AUTOSAR XML (schema 00044)
package /ComponentTypes
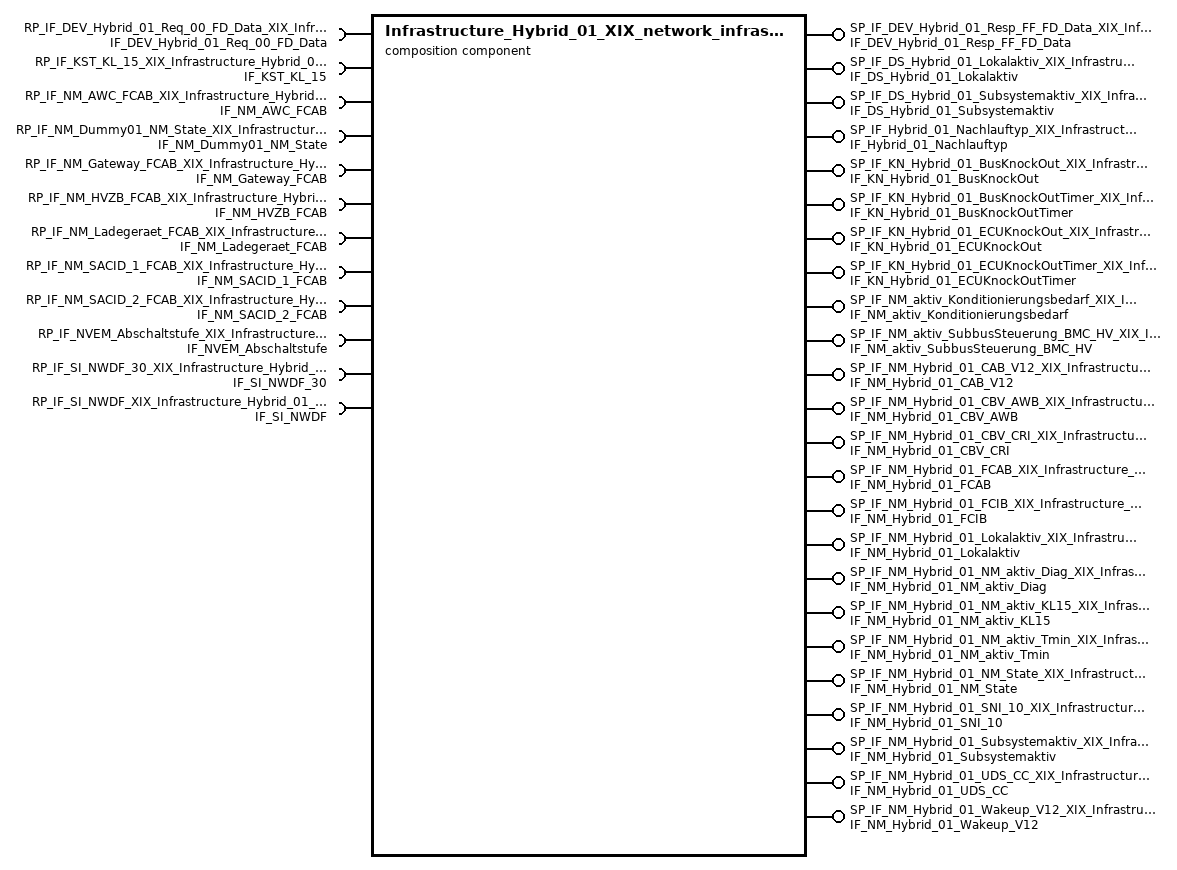
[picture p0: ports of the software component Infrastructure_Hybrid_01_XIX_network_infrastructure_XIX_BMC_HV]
  composition sw component type Infrastructure_Hybrid_01_XIX_network_infrastructure_XIX_BMC_HV
    24 x provide port:
      SP_IF_DEV_Hybrid_01_Resp_FF_FD_Data_XIX_Infrastructure_Hybrid_01_XIX_network_infrastructure_XIX_BMC_HV: nonqueued-sender-com-spec=DE_DEV_Hybrid_01_Resp_FF_FD_Data, provided-interface=IF_DEV_Hybrid_01_Resp_FF_FD_Data
      SP_IF_DS_Hybrid_01_Lokalaktiv_XIX_Infrastructure_Hybrid_01_XIX_network_infrastructure_XIX_BMC_HV: nonqueued-sender-com-spec=DE_DS_Hybrid_01_Lokalaktiv, provided-interface=IF_DS_Hybrid_01_Lokalaktiv
      SP_IF_DS_Hybrid_01_Subsystemaktiv_XIX_Infrastructure_Hybrid_01_XIX_network_infrastructure_XIX_BMC_HV: nonqueued-sender-com-spec=DE_DS_Hybrid_01_Subsystemaktiv, provided-interface=IF_DS_Hybrid_01_Subsystemaktiv
      SP_IF_Hybrid_01_Nachlauftyp_XIX_Infrastructure_Hybrid_01_XIX_network_infrastructure_XIX_BMC_HV: nonqueued-sender-com-spec=DE_Hybrid_01_Nachlauftyp, provided-interface=IF_Hybrid_01_Nachlauftyp
      SP_IF_KN_Hybrid_01_BusKnockOut_XIX_Infrastructure_Hybrid_01_XIX_network_infrastructure_XIX_BMC_HV: nonqueued-sender-com-spec=DE_KN_Hybrid_01_BusKnockOut, provided-interface=IF_KN_Hybrid_01_BusKnockOut
      SP_IF_KN_Hybrid_01_BusKnockOutTimer_XIX_Infrastructure_Hybrid_01_XIX_network_infrastructure_XIX_BMC_HV: nonqueued-sender-com-spec=DE_KN_Hybrid_01_BusKnockOutTimer, provided-interface=IF_KN_Hybrid_01_BusKnockOutTimer
      SP_IF_KN_Hybrid_01_ECUKnockOut_XIX_Infrastructure_Hybrid_01_XIX_network_infrastructure_XIX_BMC_HV: nonqueued-sender-com-spec=DE_KN_Hybrid_01_ECUKnockOut, provided-interface=IF_KN_Hybrid_01_ECUKnockOut
      SP_IF_KN_Hybrid_01_ECUKnockOutTimer_XIX_Infrastructure_Hybrid_01_XIX_network_infrastructure_XIX_BMC_HV: nonqueued-sender-com-spec=DE_KN_Hybrid_01_ECUKnockOutTimer, provided-interface=IF_KN_Hybrid_01_ECUKnockOutTimer
      SP_IF_NM_aktiv_Konditionierungsbedarf_XIX_Infrastructure_Hybrid_01_XIX_network_infrastructure_XIX_BMC_HV: nonqueued-sender-com-spec=DE_NM_aktiv_Konditionierungsbedarf, provided-interface=IF_NM_aktiv_Konditionierungsbedarf
      SP_IF_NM_aktiv_SubbusSteuerung_BMC_HV_XIX_Infrastructure_Hybrid_01_XIX_network_infrastructure_XIX_BMC_HV: nonqueued-sender-com-spec=DE_NM_aktiv_SubbusSteuerung_BMC_HV, provided-interface=IF_NM_aktiv_SubbusSteuerung_BMC_HV
      SP_IF_NM_Hybrid_01_CAB_V12_XIX_Infrastructure_Hybrid_01_XIX_network_infrastructure_XIX_BMC_HV: nonqueued-sender-com-spec=DE_NM_Hybrid_01_CAB_V12, provided-interface=IF_NM_Hybrid_01_CAB_V12
      SP_IF_NM_Hybrid_01_CBV_AWB_XIX_Infrastructure_Hybrid_01_XIX_network_infrastructure_XIX_BMC_HV: nonqueued-sender-com-spec=DE_NM_Hybrid_01_CBV_AWB, provided-interface=IF_NM_Hybrid_01_CBV_AWB
      SP_IF_NM_Hybrid_01_CBV_CRI_XIX_Infrastructure_Hybrid_01_XIX_network_infrastructure_XIX_BMC_HV: nonqueued-sender-com-spec=DE_NM_Hybrid_01_CBV_CRI, provided-interface=IF_NM_Hybrid_01_CBV_CRI
      SP_IF_NM_Hybrid_01_FCAB_XIX_Infrastructure_Hybrid_01_XIX_network_infrastructure_XIX_BMC_HV: nonqueued-sender-com-spec=DE_NM_Hybrid_01_FCAB, provided-interface=IF_NM_Hybrid_01_FCAB
      SP_IF_NM_Hybrid_01_FCIB_XIX_Infrastructure_Hybrid_01_XIX_network_infrastructure_XIX_BMC_HV: nonqueued-sender-com-spec=DE_NM_Hybrid_01_FCIB, provided-interface=IF_NM_Hybrid_01_FCIB
      SP_IF_NM_Hybrid_01_Lokalaktiv_XIX_Infrastructure_Hybrid_01_XIX_network_infrastructure_XIX_BMC_HV: nonqueued-sender-com-spec=DE_NM_Hybrid_01_Lokalaktiv, provided-interface=IF_NM_Hybrid_01_Lokalaktiv
      SP_IF_NM_Hybrid_01_NM_aktiv_Diag_XIX_Infrastructure_Hybrid_01_XIX_network_infrastructure_XIX_BMC_HV: nonqueued-sender-com-spec=DE_NM_Hybrid_01_NM_aktiv_Diag, provided-interface=IF_NM_Hybrid_01_NM_aktiv_Diag
      SP_IF_NM_Hybrid_01_NM_aktiv_KL15_XIX_Infrastructure_Hybrid_01_XIX_network_infrastructure_XIX_BMC_HV: nonqueued-sender-com-spec=DE_NM_Hybrid_01_NM_aktiv_KL15, provided-interface=IF_NM_Hybrid_01_NM_aktiv_KL15
      SP_IF_NM_Hybrid_01_NM_aktiv_Tmin_XIX_Infrastructure_Hybrid_01_XIX_network_infrastructure_XIX_BMC_HV: nonqueued-sender-com-spec=DE_NM_Hybrid_01_NM_aktiv_Tmin, provided-interface=IF_NM_Hybrid_01_NM_aktiv_Tmin
      SP_IF_NM_Hybrid_01_NM_State_XIX_Infrastructure_Hybrid_01_XIX_network_infrastructure_XIX_BMC_HV: nonqueued-sender-com-spec=DE_NM_Hybrid_01_NM_State, provided-interface=IF_NM_Hybrid_01_NM_State
      SP_IF_NM_Hybrid_01_SNI_10_XIX_Infrastructure_Hybrid_01_XIX_network_infrastructure_XIX_BMC_HV: nonqueued-sender-com-spec=DE_NM_Hybrid_01_SNI_10, provided-interface=IF_NM_Hybrid_01_SNI_10
      SP_IF_NM_Hybrid_01_Subsystemaktiv_XIX_Infrastructure_Hybrid_01_XIX_network_infrastructure_XIX_BMC_HV: nonqueued-sender-com-spec=DE_NM_Hybrid_01_Subsystemaktiv, provided-interface=IF_NM_Hybrid_01_Subsystemaktiv
      SP_IF_NM_Hybrid_01_UDS_CC_XIX_Infrastructure_Hybrid_01_XIX_network_infrastructure_XIX_BMC_HV: nonqueued-sender-com-spec=DE_NM_Hybrid_01_UDS_CC, provided-interface=IF_NM_Hybrid_01_UDS_CC
      SP_IF_NM_Hybrid_01_Wakeup_V12_XIX_Infrastructure_Hybrid_01_XIX_network_infrastructure_XIX_BMC_HV: nonqueued-sender-com-spec=DE_NM_Hybrid_01_Wakeup_V12, provided-interface=IF_NM_Hybrid_01_Wakeup_V12
    12 x require port:
      RP_IF_DEV_Hybrid_01_Req_00_FD_Data_XIX_Infrastructure_Hybrid_01_XIX_network_infrastructure_XIX_BMC_HV: nonqueued-receiver-com-spec=DE_DEV_Hybrid_01_Req_00_FD_Data, required-interface=IF_DEV_Hybrid_01_Req_00_FD_Data
      RP_IF_KST_KL_15_XIX_Infrastructure_Hybrid_01_XIX_network_infrastructure_XIX_BMC_HV: nonqueued-receiver-com-spec=DE_KST_KL_15, required-interface=IF_KST_KL_15
      RP_IF_NM_AWC_FCAB_XIX_Infrastructure_Hybrid_01_XIX_network_infrastructure_XIX_BMC_HV: nonqueued-receiver-com-spec=DE_NM_AWC_FCAB, required-interface=IF_NM_AWC_FCAB
      RP_IF_NM_Dummy01_NM_State_XIX_Infrastructure_Hybrid_01_XIX_network_infrastructure_XIX_BMC_HV: nonqueued-receiver-com-spec=DE_NM_Dummy01_NM_State, required-interface=IF_NM_Dummy01_NM_State
      RP_IF_NM_Gateway_FCAB_XIX_Infrastructure_Hybrid_01_XIX_network_infrastructure_XIX_BMC_HV: nonqueued-receiver-com-spec=DE_NM_Gateway_FCAB, required-interface=IF_NM_Gateway_FCAB
      RP_IF_NM_HVZB_FCAB_XIX_Infrastructure_Hybrid_01_XIX_network_infrastructure_XIX_BMC_HV: nonqueued-receiver-com-spec=DE_NM_HVZB_FCAB, required-interface=IF_NM_HVZB_FCAB
      RP_IF_NM_Ladegeraet_FCAB_XIX_Infrastructure_Hybrid_01_XIX_network_infrastructure_XIX_BMC_HV: nonqueued-receiver-com-spec=DE_NM_Ladegeraet_FCAB, required-interface=IF_NM_Ladegeraet_FCAB
      RP_IF_NM_SACID_1_FCAB_XIX_Infrastructure_Hybrid_01_XIX_network_infrastructure_XIX_BMC_HV: nonqueued-receiver-com-spec=DE_NM_SACID_1_FCAB, required-interface=IF_NM_SACID_1_FCAB
      RP_IF_NM_SACID_2_FCAB_XIX_Infrastructure_Hybrid_01_XIX_network_infrastructure_XIX_BMC_HV: nonqueued-receiver-com-spec=DE_NM_SACID_2_FCAB, required-interface=IF_NM_SACID_2_FCAB
      RP_IF_NVEM_Abschaltstufe_XIX_Infrastructure_Hybrid_01_XIX_network_infrastructure_XIX_BMC_HV: nonqueued-receiver-com-spec=DE_NVEM_Abschaltstufe, required-interface=IF_NVEM_Abschaltstufe
      RP_IF_SI_NWDF_30_XIX_Infrastructure_Hybrid_01_XIX_network_infrastructure_XIX_BMC_HV: nonqueued-receiver-com-spec=DE_SI_NWDF_30, required-interface=IF_SI_NWDF_30
      RP_IF_SI_NWDF_XIX_Infrastructure_Hybrid_01_XIX_network_infrastructure_XIX_BMC_HV: nonqueued-receiver-com-spec=DE_SI_NWDF, required-interface=IF_SI_NWDF
